VERSION ""

NS_ :

BU_: EBCM EON CAM RADAR PCM EPS VSA SCM BDY XXX EPB

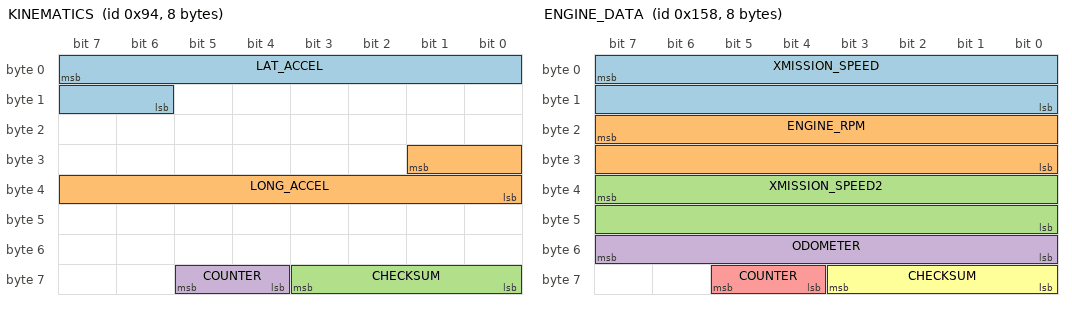
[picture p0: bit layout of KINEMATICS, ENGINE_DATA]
BO_ 148 KINEMATICS: 8 XXX
 SG_ LAT_ACCEL : 7|10@0+ (-0.035,17.92) [-20|20] "m/s2" EON
 SG_ LONG_ACCEL : 25|10@0+ (-0.035,17.92) [-20|20] "m/s2" EON
 SG_ CHECKSUM : 59|4@0+ (1,0) [0|3] "" EON
 SG_ COUNTER : 61|2@0+ (1,0) [0|3] "" EON

 BO_ 344 ENGINE_DATA: 8 PCM
 SG_ XMISSION_SPEED : 7|16@0+ (0.01,0) [0|250] "kph" EON
 SG_ ENGINE_RPM : 23|16@0+ (1,0) [0|15000] "rpm" EON
 SG_ XMISSION_SPEED2 : 39|16@0+ (0.01,0) [0|250] "kph" EON
 SG_ ODOMETER : 55|8@0+ (10,0) [0|2550] "m" XXX
 SG_ COUNTER : 61|2@0+ (1,0) [0|3] "" EON
 SG_ CHECKSUM : 59|4@0+ (1,0) [0|15] "" EON

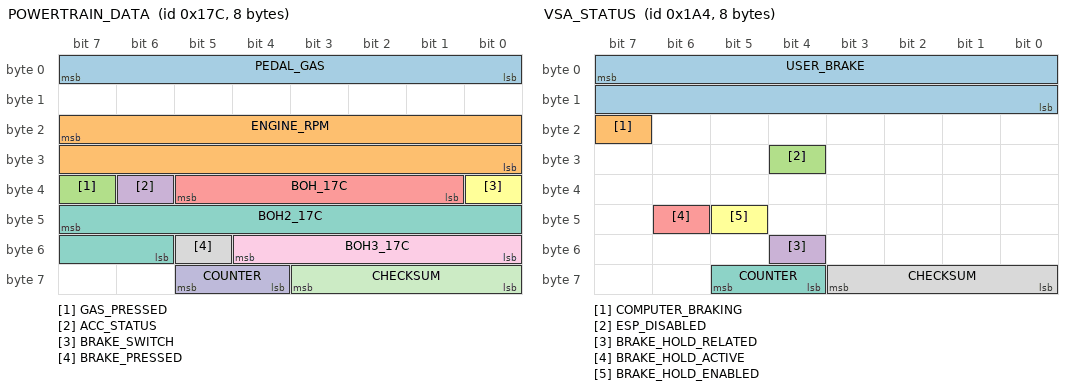
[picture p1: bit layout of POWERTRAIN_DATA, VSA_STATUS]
BO_ 380 POWERTRAIN_DATA: 8 PCM
 SG_ PEDAL_GAS : 7|8@0+ (1,0) [0|255] "" EON
 SG_ ENGINE_RPM : 23|16@0+ (1,0) [0|15000] "rpm" EON
 SG_ GAS_PRESSED : 39|1@0+ (1,0) [0|1] "" EON
 SG_ ACC_STATUS : 38|1@0+ (1,0) [0|1] "" EON
 SG_ BOH_17C : 37|5@0+ (1,0) [0|1] "" EON
 SG_ BRAKE_SWITCH : 32|1@0+ (1,0) [0|1] "" EON
 SG_ BOH2_17C : 47|10@0+ (1,0) [0|1] "" EON
 SG_ BRAKE_PRESSED : 53|1@0+ (1,0) [0|1] "" EON
 SG_ BOH3_17C : 52|5@0+ (1,0) [0|1] "" EON
 SG_ COUNTER : 61|2@0+ (1,0) [0|3] "" EON
 SG_ CHECKSUM : 59|4@0+ (1,0) [0|3] "" EON

BO_ 420 VSA_STATUS: 8 VSA
 SG_ USER_BRAKE : 7|16@0+ (0.015625,-1.609375) [0|1000] "" EON
 SG_ COMPUTER_BRAKING : 23|1@0+ (1,0) [0|1] "" EON
 SG_ ESP_DISABLED : 28|1@0+ (1,0) [0|1] "" EON
 SG_ BRAKE_HOLD_RELATED : 52|1@0+ (1,0) [0|1] "" XXX
 SG_ BRAKE_HOLD_ACTIVE : 46|1@0+ (1,0) [0|1] "" EON
 SG_ BRAKE_HOLD_ENABLED : 45|1@0+ (1,0) [0|1] "" EON
 SG_ COUNTER : 61|2@0+ (1,0) [0|3] "" EON
 SG_ CHECKSUM : 59|4@0+ (1,0) [0|15] "" EON

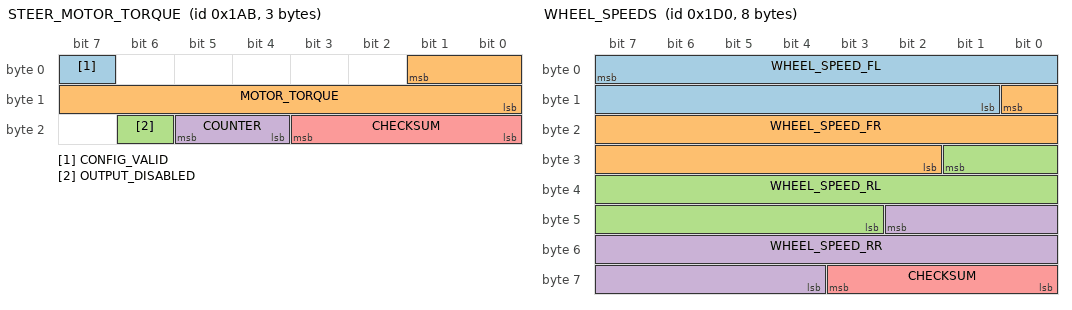
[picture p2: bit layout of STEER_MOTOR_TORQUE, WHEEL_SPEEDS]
BO_ 427 STEER_MOTOR_TORQUE: 3 EPS
 SG_ CONFIG_VALID : 7|1@0+ (1,0) [0|1] "" EON
 SG_ MOTOR_TORQUE : 1|10@0+ (1,0) [0|256] "" EON
 SG_ OUTPUT_DISABLED : 22|1@0+ (1,0) [0|1] "" EON
 SG_ COUNTER : 21|2@0+ (1,0) [0|3] "" EON
 SG_ CHECKSUM : 19|4@0+ (1,0) [0|15] "" EON

 BO_ 464 WHEEL_SPEEDS: 8 VSA
 SG_ WHEEL_SPEED_FL : 7|15@0+ (0.01,0) [0|250] "kph" EON
 SG_ WHEEL_SPEED_FR : 8|15@0+ (0.01,0) [0|250] "kph" EON
 SG_ WHEEL_SPEED_RL : 25|15@0+ (0.01,0) [0|250] "kph" EON
 SG_ WHEEL_SPEED_RR : 42|15@0+ (0.01,0) [0|250] "kph" EON
 SG_ CHECKSUM : 59|4@0+ (1,0) [0|3] "" EON

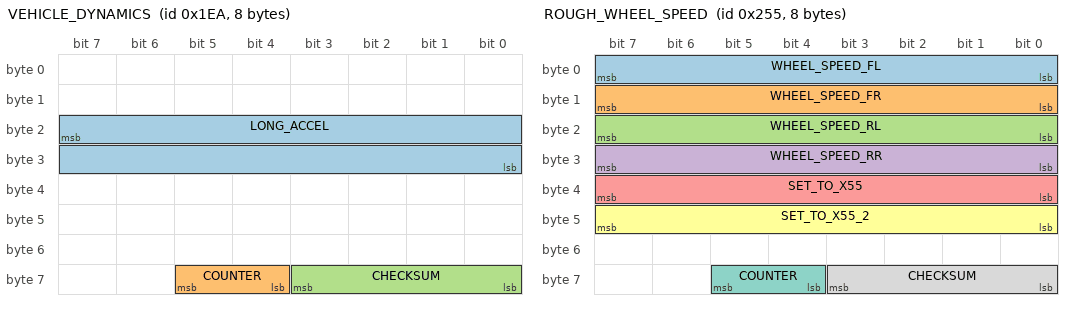
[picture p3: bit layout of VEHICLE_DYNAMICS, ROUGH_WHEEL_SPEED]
BO_ 490 VEHICLE_DYNAMICS: 8 VSA
 SG_ LONG_ACCEL : 23|16@0- (0.0015384,0) [-20|20] "m/s2" EON
 SG_ COUNTER : 61|2@0+ (1,0) [0|3] "" EON
 SG_ CHECKSUM : 59|4@0+ (1,0) [0|3] "" EON

BO_ 597 ROUGH_WHEEL_SPEED: 8 VSA
 SG_ WHEEL_SPEED_FL : 7|8@0+ (1,0) [0|255] "mph" EON
 SG_ WHEEL_SPEED_FR : 15|8@0+ (1,0) [0|255] "mph" EON
 SG_ WHEEL_SPEED_RL : 23|8@0+ (1,0) [0|255] "mph" EON
 SG_ WHEEL_SPEED_RR : 31|8@0+ (1,0) [0|255] "mph" EON
 SG_ SET_TO_X55 : 39|8@0+ (1,0) [0|255] "" EON
 SG_ SET_TO_X55_2 : 47|8@0+ (1,0) [0|255] "" EON
 SG_ COUNTER : 61|2@0+ (1,0) [0|3] "" EON
 SG_ CHECKSUM : 59|4@0+ (1,0) [0|15] "" EON

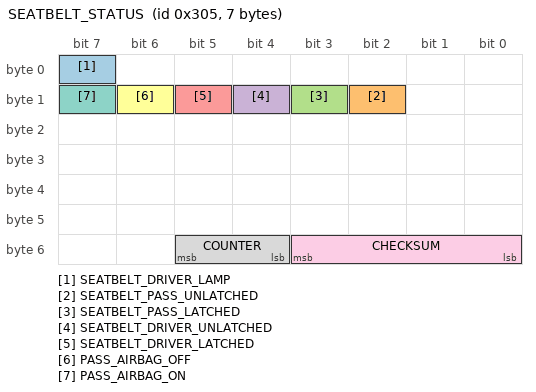
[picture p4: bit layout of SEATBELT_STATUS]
BO_ 773 SEATBELT_STATUS: 7 BDY
 SG_ SEATBELT_DRIVER_LAMP : 7|1@0+ (1,0) [0|1] "" EON
 SG_ SEATBELT_PASS_UNLATCHED : 10|1@0+ (1,0) [0|1] "" EON
 SG_ SEATBELT_PASS_LATCHED : 11|1@0+ (1,0) [0|1] "" EON
 SG_ SEATBELT_DRIVER_UNLATCHED : 12|1@0+ (1,0) [0|1] "" EON
 SG_ SEATBELT_DRIVER_LATCHED : 13|1@0+ (1,0) [0|1] "" EON
 SG_ PASS_AIRBAG_OFF : 14|1@0+ (1,0) [0|1] "" EON
 SG_ PASS_AIRBAG_ON : 15|1@0+ (1,0) [0|1] "" EON
 SG_ COUNTER : 53|2@0+ (1,0) [0|3] "" EON
 SG_ CHECKSUM : 51|4@0+ (1,0) [0|3] "" EON

BO_ 829 LKAS_HUD: 5 ADAS
 SG_ CAM_TEMP_HIGH : 7|1@0+ (1,0) [0|255] "" BDY
 SG_ SET_ME_X41 : 6|7@0+ (1,0) [0|127] "" BDY
 SG_ BOH : 6|7@0+ (1,0) [0|127] "" BDY
 SG_ DASHED_LANES : 14|1@0+ (1,0) [0|1] "" BDY
 SG_ DTC : 13|1@0+ (1,0) [0|1] "" BDY
 SG_ LKAS_PROBLEM : 12|1@0+ (1,0) [0|1] "" BDY
 SG_ LKAS_OFF : 11|1@0+ (1,0) [0|1] "" BDY
 SG_ SOLID_LANES : 10|1@0+ (1,0) [0|1] "" BDY
 SG_ LDW_RIGHT : 9|1@0+ (1,0) [0|1] "" BDY
 SG_ STEERING_REQUIRED : 8|1@0+ (1,0) [0|1] "" BDY
 SG_ BOH : 23|2@0+ (1,0) [0|4] "" BDY
 SG_ LDW_PROBLEM : 21|1@0+ (1,0) [0|1] "" BDY
 SG_ BEEP : 17|2@0+ (1,0) [0|1] "" BDY
 SG_ LDW_ON : 28|1@0+ (1,0) [0|1] "" BDY
 SG_ LDW_OFF : 27|1@0+ (1,0) [0|1] "" BDY
 SG_ CLEAN_WINDSHIELD : 26|1@0+ (1,0) [0|1] "" BDY
 SG_ SET_ME_X48 : 31|8@0+ (1,0) [0|255] "" BDY
 SG_ COUNTER : 37|2@0+ (1,0) [0|3] "" BDY
 SG_ CHECKSUM : 35|4@0+ (1,0) [0|15] "" BDY
